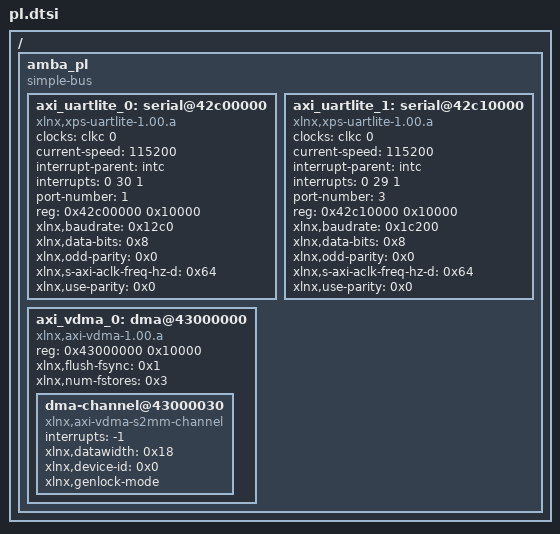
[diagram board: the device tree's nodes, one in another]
/*
 * CAUTION: This file is automatically generated by Xilinx.
 * Version:  
 * Today is: Sun Jun 28 21:24:58 2015
*/


/ {
	amba_pl: amba_pl {
		#address-cells = <1>;
		#size-cells = <1>;
		compatible = "simple-bus";
		ranges ;
		axi_uartlite_0: serial@42c00000 {
			clock-names = "ref_clk";
			clocks = "clkc 0";
			compatible = "xlnx,xps-uartlite-1.00.a";
			current-speed = <115200>;
			device_type = "serial";
			interrupt-parent = <&intc>;
			interrupts = <0 30 1>;
			port-number = <1>;
			reg = <0x42c00000 0x10000>;
			xlnx,baudrate = <0x12c0>;
			xlnx,data-bits = <0x8>;
			xlnx,odd-parity = <0x0>;
			xlnx,s-axi-aclk-freq-hz-d = <0x64>;
			xlnx,use-parity = <0x0>;
		};
		axi_uartlite_1: serial@42c10000 {
			clock-names = "ref_clk";
			clocks = "clkc 0";
			compatible = "xlnx,xps-uartlite-1.00.a";
			current-speed = <115200>;
			device_type = "serial";
			interrupt-parent = <&intc>;
			interrupts = <0 29 1>;
			port-number = <3>;
			reg = <0x42c10000 0x10000>;
			xlnx,baudrate = <0x1c200>;
			xlnx,data-bits = <0x8>;
			xlnx,odd-parity = <0x0>;
			xlnx,s-axi-aclk-freq-hz-d = <0x64>;
			xlnx,use-parity = <0x0>;
		};
		axi_vdma_0: dma@43000000 {
			#dma-cells = <1>;
			compatible = "xlnx,axi-vdma-1.00.a";
			reg = <0x43000000 0x10000>;
			xlnx,flush-fsync = <0x1>;
			xlnx,num-fstores = <0x3>;
			dma-channel@43000030 {
				compatible = "xlnx,axi-vdma-s2mm-channel";
				interrupts = <-1>;
				xlnx,datawidth = <0x18>;
				xlnx,device-id = <0x0>;
				xlnx,genlock-mode ;
			};
		};
	};
};
